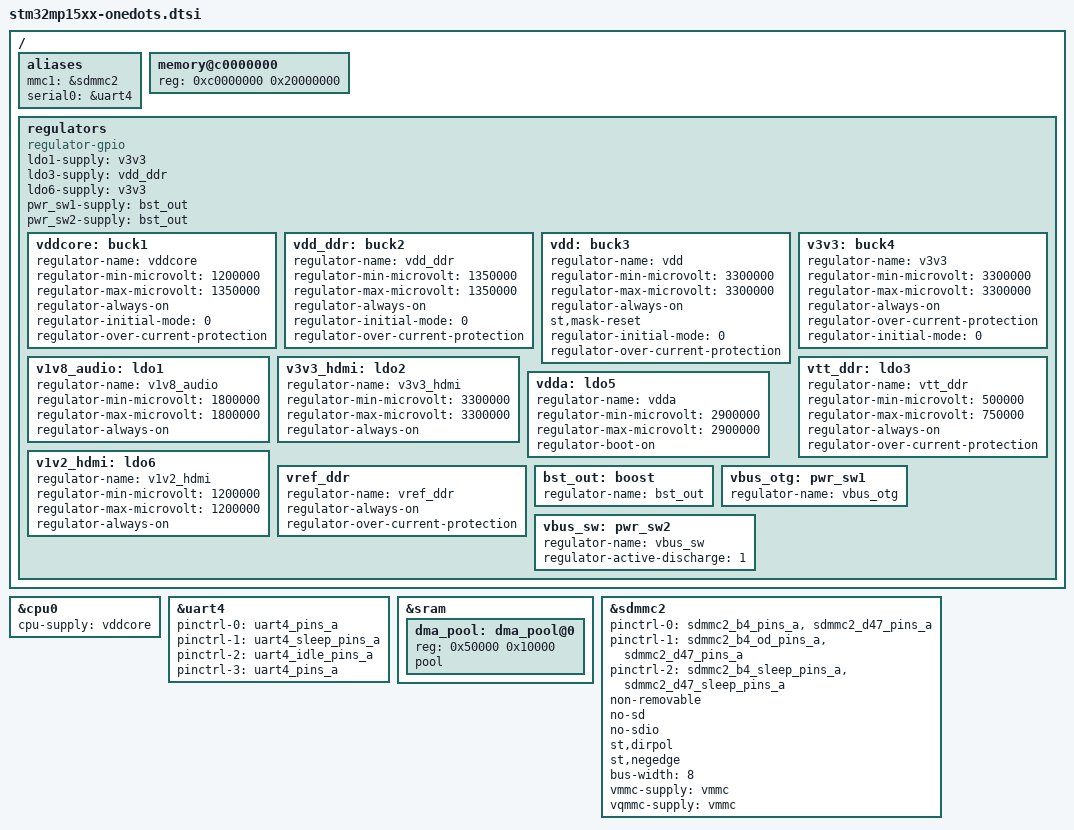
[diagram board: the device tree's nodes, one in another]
// SPDX-License-Identifier: (GPL-2.0+ OR BSD-3-Clause)
/*
 * Copyright (C) STMicroelectronics 2019 - All Rights Reserved
 * Author: Alexandre Torgue <alexandre.torgue@st.com> for STMicroelectronics.
 */

/ {
		// 添加别名节点来固定设备映射
	aliases {
		mmc1 = &sdmmc2;  // eMMC (你的主要存储)
		serial0 = &uart4;
	};
	memory@c0000000 {
		device_type = "memory";
		reg = <0xc0000000 0x20000000>;
	};

	regulators {
			compatible = "regulator-gpio";
			ldo1-supply = <&v3v3>;
			ldo3-supply = <&vdd_ddr>;
			ldo6-supply = <&v3v3>;
			pwr_sw1-supply = <&bst_out>;
			pwr_sw2-supply = <&bst_out>;
			
			vddcore: buck1 {
				regulator-name = "vddcore";
				regulator-min-microvolt = <1200000>;
				regulator-max-microvolt = <1350000>;
				regulator-always-on;
				regulator-initial-mode = <0>;
				regulator-over-current-protection;
			};

			vdd_ddr: buck2 {
				regulator-name = "vdd_ddr";
				regulator-min-microvolt = <1350000>;
				regulator-max-microvolt = <1350000>;
				regulator-always-on;
				regulator-initial-mode = <0>;
				regulator-over-current-protection;
			};

			vdd: buck3 {
				regulator-name = "vdd";
				regulator-min-microvolt = <3300000>;
				regulator-max-microvolt = <3300000>;
				regulator-always-on;
				st,mask-reset;
				regulator-initial-mode = <0>;
				regulator-over-current-protection;
			};

			v3v3: buck4 {
				regulator-name = "v3v3";
				regulator-min-microvolt = <3300000>;
				regulator-max-microvolt = <3300000>;
				regulator-always-on;
				regulator-over-current-protection;
				regulator-initial-mode = <0>;
			};

			v1v8_audio: ldo1 {
				regulator-name = "v1v8_audio";
				regulator-min-microvolt = <1800000>;
				regulator-max-microvolt = <1800000>;
				regulator-always-on;
				//interrupts = <IT_CURLIM_LDO1 0>;
			};

			v3v3_hdmi: ldo2 {
				regulator-name = "v3v3_hdmi";
				regulator-min-microvolt = <3300000>;
				regulator-max-microvolt = <3300000>;
				regulator-always-on;
				//interrupts = <IT_CURLIM_LDO2 0>;
			};

			vtt_ddr: ldo3 {
				regulator-name = "vtt_ddr";
				regulator-min-microvolt = <500000>;
				regulator-max-microvolt = <750000>;
				regulator-always-on;
				regulator-over-current-protection;
			};
			vdda: ldo5 {
				regulator-name = "vdda";
				regulator-min-microvolt = <2900000>;
				regulator-max-microvolt = <2900000>;
				//interrupts = <IT_CURLIM_LDO5 0>;
				regulator-boot-on;
			};

			v1v2_hdmi: ldo6 {
				regulator-name = "v1v2_hdmi";
				regulator-min-microvolt = <1200000>;
				regulator-max-microvolt = <1200000>;
				regulator-always-on;
				//interrupts = <IT_CURLIM_LDO6 0>;
			};

			vref_ddr: vref_ddr {
				regulator-name = "vref_ddr";
				regulator-always-on;
				regulator-over-current-protection;
			};

			 bst_out: boost {
				regulator-name = "bst_out";
				//interrupts = <IT_OCP_BOOST 0>;
			 };

			vbus_otg: pwr_sw1 {
				regulator-name = "vbus_otg";
				//interrupts = <IT_OCP_OTG 0>;
			 };

			 vbus_sw: pwr_sw2 {
				regulator-name = "vbus_sw";
				//interrupts = <IT_OCP_SWOUT 0>;
				regulator-active-discharge = <1>;
			 };
	};
};

&cpu0{
	cpu-supply = <&vddcore>;
};

/*DEBUG*/
&uart4 {
	pinctrl-names = "default", "sleep", "idle";
	pinctrl-0 = <&uart4_pins_a>;
	pinctrl-1 = <&uart4_sleep_pins_a>;
	pinctrl-2 = <&uart4_idle_pins_a>;
	pinctrl-3 = <&uart4_pins_a>;
	/delete-property/dmas;
	/delete-property/dma-names;
	status = "okay";
};

&sram {
	dma_pool: dma_pool@0 {
		reg = <0x50000 0x10000>;
		pool;
	};
};

/*emmc*/
&sdmmc2 {
        pinctrl-names = "default", "opendrain", "sleep";
        pinctrl-0 = <&sdmmc2_b4_pins_a &sdmmc2_d47_pins_a>;
        pinctrl-1 = <&sdmmc2_b4_od_pins_a &sdmmc2_d47_pins_a>;
        pinctrl-2 = <&sdmmc2_b4_sleep_pins_a &sdmmc2_d47_sleep_pins_a>;
        non-removable;
        no-sd;
        no-sdio;
        st,dirpol;
        st,negedge;
        bus-width = <8>;
        vmmc-supply = <&vmmc>;
        vqmmc-supply = <&vmmc>;
        status = "okay";
};
